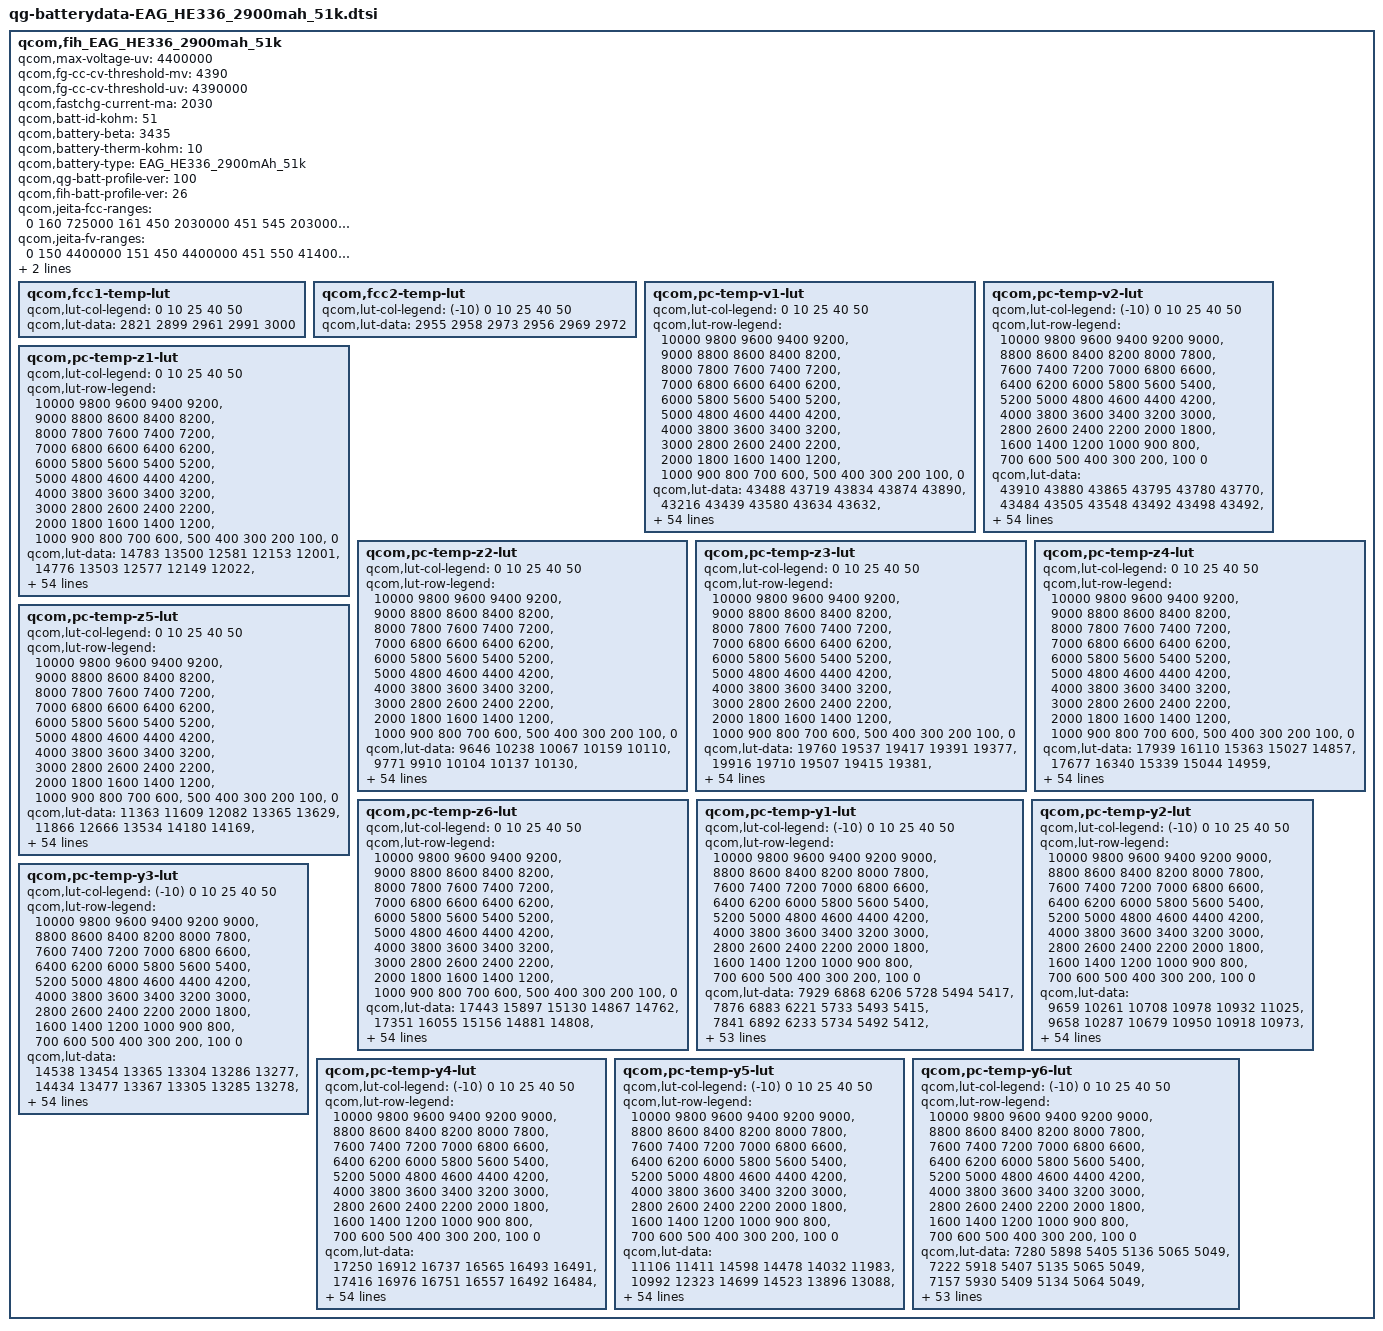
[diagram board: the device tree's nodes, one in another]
qcom,fih_EAG_HE336_2900mah_51k {
	/* 3486571_FIH_EaglesScud_2990mAh_averaged_MasterSlave_Jul3rd2018 */
	qcom,max-voltage-uv = <4400000>;
	qcom,fg-cc-cv-threshold-mv = <4390>;
	qcom,fg-cc-cv-threshold-uv = <4390000>;
	qcom,fastchg-current-ma = <2030>;
	qcom,batt-id-kohm = <51>;
	qcom,battery-beta = <3435>;
	qcom,battery-therm-kohm = <10>;
	qcom,battery-type =
		"EAG_HE336_2900mAh_51k";
	qcom,qg-batt-profile-ver = <100>;
	qcom,fih-batt-profile-ver = <26>; // RHD 51K use 25

	qcom,jeita-fcc-ranges = <0   160   725000
				 161 450  2030000
				 451 545  2030000
				 546 550  100000>;
	qcom,jeita-fv-ranges =  <0   150  4400000
				 151 450  4400000
				 451 550  4140000>;

	qcom,jeita-soft-thresholds = <0x257d 0xfb3>; 
	qcom,jeita-hard-thresholds = <0x3733 0xc19>;

	qcom,fcc1-temp-lut {
		qcom,lut-col-legend = <0 10 25 40 50>;
		qcom,lut-data = <2821 2899 2961 2991 3000>;
	};

	qcom,fcc2-temp-lut {
		qcom,lut-col-legend = <(-10) 0 10 25 40 50>;
		qcom,lut-data = <2955 2958 2973 2956 2969 2972>;
	};

	qcom,pc-temp-v1-lut {
		qcom,lut-col-legend = <0 10 25 40 50>;
		qcom,lut-row-legend = <10000 9800 9600 9400 9200>,
			<9000 8800 8600 8400 8200>,
			<8000 7800 7600 7400 7200>,
			<7000 6800 6600 6400 6200>,
			<6000 5800 5600 5400 5200>,
			<5000 4800 4600 4400 4200>,
			<4000 3800 3600 3400 3200>,
			<3000 2800 2600 2400 2200>,
			<2000 1800 1600 1400 1200>,
			<1000 900 800 700 600>,
			<500 400 300 200 100>,
			<0>;
		qcom,lut-data = <43488 43719 43834 43874 43890>,
			<43216 43439 43580 43634 43632>,
			<42958 43182 43330 43388 43393>,
			<42716 42938 43086 43147 43155>,
			<42489 42699 42845 42909 42920>,
			<42268 42464 42606 42672 42686>,
			<42052 42235 42368 42437 42453>,
			<41843 42015 42134 42203 42222>,
			<41638 41802 41906 41972 41992>,
			<41437 41593 41683 41741 41761>,
			<41241 41386 41464 41515 41532>,
			<41055 41185 41249 41293 41311>,
			<40880 40998 41041 41076 41093>,
			<40679 40826 40851 40869 40883>,
			<40394 40629 40670 40669 40676>,
			<40090 40348 40470 40475 40477>,
			<39901 40059 40229 40281 40285>,
			<39786 39889 40005 40092 40101>,
			<39685 39788 39852 39920 39929>,
			<39572 39687 39730 39768 39774>,
			<39458 39555 39581 39603 39609>,
			<39340 39403 39383 39383 39402>,
			<39213 39225 39175 39144 39171>,
			<39085 38987 38978 38959 38981>,
			<38964 38769 38786 38810 38821>,
			<38847 38637 38649 38682 38683>,
			<38736 38538 38562 38569 38565>,
			<38629 38468 38490 38468 38461>,
			<38527 38419 38413 38376 38367>,
			<38448 38381 38337 38292 38279>,
			<38390 38340 38270 38218 38202>,
			<38343 38301 38211 38151 38133>,
			<38305 38264 38159 38092 38072>,
			<38275 38227 38114 38041 38015>,
			<38246 38192 38075 37998 37965>,
			<38215 38158 38037 37955 37914>,
			<38183 38128 38001 37908 37855>,
			<38143 38090 37962 37856 37790>,
			<38089 38027 37903 37789 37717>,
			<38020 37936 37816 37705 37634>,
			<37926 37834 37717 37607 37539>,
			<37792 37715 37604 37497 37429>,
			<37653 37579 37473 37370 37300>,
			<37506 37416 37312 37209 37138>,
			<37360 37269 37171 37069 37002>,
			<37252 37170 37074 36981 36921>,
			<37213 37145 37047 36959 36898>,
			<37182 37118 37032 36940 36879>,
			<37154 37093 37012 36922 36862>,
			<37103 37051 36970 36871 36804>,
			<36911 36842 36742 36610 36520>,
			<36479 36402 36310 36175 36083>,
			<35915 35835 35744 35605 35511>,
			<35159 35064 34975 34825 34732>,
			<33922 33850 33772 33618 33523>,
			<30000 30000 30000 30000 30000>;
	};

	qcom,pc-temp-v2-lut {
		qcom,lut-col-legend = <(-10) 0 10 25 40 50>;
		qcom,lut-row-legend = <10000 9800 9600 9400 9200 9000>,
			<8800 8600 8400 8200 8000 7800>,
			<7600 7400 7200 7000 6800 6600>,
			<6400 6200 6000 5800 5600 5400>,
			<5200 5000 4800 4600 4400 4200>,
			<4000 3800 3600 3400 3200 3000>,
			<2800 2600 2400 2200 2000 1800>,
			<1600 1400 1200 1000 900 800>,
			<700 600 500 400 300 200>,
			<100 0>;
		qcom,lut-data = <43910 43880 43865 43795 43780 43770>,
			<43484 43505 43548 43492 43498 43492>,
			<43098 43165 43252 43208 43230 43227>,
			<42755 42867 42978 42946 42976 42975>,
			<42445 42606 42727 42705 42736 42737>,
			<42172 42358 42485 42471 42501 42503>,
			<41937 42110 42246 42236 42266 42268>,
			<41726 41869 42012 42005 42034 42036>,
			<41515 41616 41785 41779 41805 41807>,
			<41281 41333 41561 41556 41579 41580>,
			<41092 41111 41347 41338 41356 41357>,
			<40996 41010 41151 41126 41139 41138>,
			<40917 40937 40964 40918 40925 40922>,
			<40737 40784 40757 40706 40718 40716>,
			<40169 40384 40527 40484 40514 40515>,
			<39621 39980 40289 40272 40317 40321>,
			<39409 39758 40046 40080 40131 40133>,
			<39270 39588 39801 39902 39952 39951>,
			<39119 39408 39589 39734 39780 39778>,
			<38945 39216 39407 39585 39619 39619>,
			<38777 39029 39232 39426 39448 39450>,
			<38621 38853 39049 39213 39226 39229>,
			<38474 38687 38870 38963 38980 38985>,
			<38358 38535 38712 38766 38788 38795>,
			<38266 38394 38573 38622 38643 38647>,
			<38190 38272 38448 38500 38518 38521>,
			<38131 38174 38339 38391 38406 38408>,
			<38083 38091 38240 38294 38307 38308>,
			<38036 38027 38148 38205 38217 38217>,
			<37990 37980 38059 38125 38134 38133>,
			<37945 37941 37982 38052 38060 38056>,
			<37899 37902 37914 37981 37993 37987>,
			<37854 37866 37856 37914 37932 37923>,
			<37806 37828 37810 37850 37868 37857>,
			<37754 37789 37778 37792 37801 37789>,
			<37699 37747 37746 37735 37730 37714>,
			<37639 37699 37706 37675 37643 37614>,
			<37573 37646 37661 37615 37543 37495>,
			<37502 37584 37606 37549 37454 37394>,
			<37426 37512 37539 37481 37383 37318>,
			<37346 37429 37460 37405 37310 37242>,
			<37267 37328 37367 37312 37214 37146>,
			<37189 37205 37254 37195 37097 37034>,
			<37113 37082 37104 37056 36956 36895>,
			<37036 36969 36962 36924 36847 36792>,
			<36945 36891 36884 36878 36811 36756>,
			<36887 36855 36858 36864 36801 36745>,
			<36823 36819 36832 36843 36783 36730>,
			<36735 36776 36794 36818 36751 36698>,
			<36595 36689 36709 36747 36651 36578>,
			<36346 36468 36464 36491 36343 36242>,
			<35944 36026 35990 36020 35843 35735>,
			<35359 35414 35348 35412 35193 35078>,
			<34502 34544 34469 34594 34312 34187>,
			<33035 33164 33243 33342 33005 32858>,
			<29054 29382 28326 28910 28501 28490>;
	};

	qcom,pc-temp-z1-lut {
		qcom,lut-col-legend = <0 10 25 40 50>;
		qcom,lut-row-legend = <10000 9800 9600 9400 9200>,
			<9000 8800 8600 8400 8200>,
			<8000 7800 7600 7400 7200>,
			<7000 6800 6600 6400 6200>,
			<6000 5800 5600 5400 5200>,
			<5000 4800 4600 4400 4200>,
			<4000 3800 3600 3400 3200>,
			<3000 2800 2600 2400 2200>,
			<2000 1800 1600 1400 1200>,
			<1000 900 800 700 600>,
			<500 400 300 200 100>,
			<0>;
		qcom,lut-data = <14783 13500 12581 12153 12001>,
			<14776 13503 12577 12149 12022>,
			<14773 13492 12571 12147 12019>,
			<14776 13477 12562 12142 12016>,
			<14780 13471 12549 12131 12011>,
			<14783 13469 12538 12120 12007>,
			<14785 13468 12527 12115 12005>,
			<14787 13461 12520 12111 12003>,
			<14789 13447 12516 12109 12002>,
			<14786 13441 12513 12107 12000>,
			<14774 13438 12512 12107 11998>,
			<14738 13434 12516 12108 11998>,
			<14669 13421 12519 12109 11998>,
			<14604 13391 12509 12108 11998>,
			<14547 13366 12487 12103 11997>,
			<14497 13349 12480 12099 11997>,
			<14469 13338 12479 12100 11998>,
			<14456 13340 12479 12102 12000>,
			<14460 13363 12485 12105 12002>,
			<14502 13386 12500 12108 12002>,
			<14581 13397 12511 12110 12003>,
			<14630 13406 12517 12110 12004>,
			<14637 13415 12522 12111 12005>,
			<14634 13427 12526 12112 12007>,
			<14633 13435 12530 12115 12010>,
			<14642 13437 12534 12120 12014>,
			<14650 13434 12541 12124 12017>,
			<14655 13435 12549 12129 12020>,
			<14665 13453 12554 12134 12024>,
			<14680 13472 12560 12139 12028>,
			<14703 13476 12565 12145 12032>,
			<14725 13473 12570 12149 12035>,
			<14734 13474 12576 12152 12037>,
			<14739 13489 12582 12156 12040>,
			<14741 13507 12589 12162 12044>,
			<14730 13517 12597 12168 12047>,
			<14706 13527 12609 12172 12051>,
			<14698 13537 12621 12177 12054>,
			<14724 13554 12625 12181 12058>,
			<14759 13581 12627 12186 12060>,
			<14782 13593 12630 12190 12063>,
			<14800 13594 12637 12194 12066>,
			<14799 13597 12644 12197 12070>,
			<14778 13613 12648 12202 12074>,
			<14797 13602 12659 12207 12077>,
			<14796 13591 12669 12208 12077>,
			<14767 13596 12654 12212 12080>,
			<14738 13600 12669 12214 12080>,
			<14731 13602 12675 12215 12084>,
			<14783 13629 12664 12223 12088>,
			<14846 13641 12682 12234 12095>,
			<14805 13649 12698 12245 12105>,
			<14816 13696 12735 12257 12117>,
			<14903 13740 12763 12281 12132>,
			<14903 13740 12763 12281 12132>,
			<14903 13740 12763 12281 12132>;
	};

	qcom,pc-temp-z2-lut {
		qcom,lut-col-legend = <0 10 25 40 50>;
		qcom,lut-row-legend = <10000 9800 9600 9400 9200>,
			<9000 8800 8600 8400 8200>,
			<8000 7800 7600 7400 7200>,
			<7000 6800 6600 6400 6200>,
			<6000 5800 5600 5400 5200>,
			<5000 4800 4600 4400 4200>,
			<4000 3800 3600 3400 3200>,
			<3000 2800 2600 2400 2200>,
			<2000 1800 1600 1400 1200>,
			<1000 900 800 700 600>,
			<500 400 300 200 100>,
			<0>;
		qcom,lut-data = <9646 10238 10067 10159 10110>,
			<9771 9910 10104 10137 10130>,
			<9857 9912 10118 10190 10136>,
			<9887 9910 10107 10196 10132>,
			<9905 9900 10082 10158 10121>,
			<9911 9878 10061 10130 10108>,
			<9902 9856 10040 10129 10085>,
			<9885 9844 10028 10129 10042>,
			<9875 9835 10037 10131 10023>,
			<9870 9830 10057 10135 10027>,
			<9865 9828 10068 10138 10036>,
			<9856 9827 10072 10133 10043>,
			<9841 9866 10077 10122 10051>,
			<9832 10004 10092 10116 10054>,
			<9828 10079 10115 10113 10053>,
			<9825 10007 10121 10111 10053>,
			<9828 9906 10107 10106 10056>,
			<9855 9893 10094 10103 10061>,
			<9883 9928 10104 10106 10069>,
			<9882 9963 10137 10128 10086>,
			<9862 9982 10170 10162 10113>,
			<9847 9996 10208 10232 10171>,
			<9828 10003 10234 10318 10247>,
			<9808 10007 10212 10322 10265>,
			<9805 10010 10150 10239 10252>,
			<9807 10015 10125 10181 10235>,
			<9810 10023 10147 10212 10208>,
			<9816 10027 10171 10264 10163>,
			<9823 10025 10175 10264 10127>,
			<9827 10022 10176 10200 10096>,
			<9827 10021 10175 10156 10071>,
			<9827 10021 10172 10164 10053>,
			<9829 10022 10168 10181 10039>,
			<9831 10030 10173 10198 10041>,
			<9835 10042 10191 10217 10079>,
			<9840 10045 10205 10240 10129>,
			<9848 10045 10211 10275 10188>,
			<9858 10046 10217 10317 10250>,
			<9871 10055 10232 10350 10266>,
			<9885 10072 10265 10379 10266>,
			<9897 10083 10284 10393 10266>,
			<9909 10087 10283 10378 10268>,
			<9883 10093 10280 10362 10269>,
			<9762 10105 10288 10365 10273>,
			<9869 10229 10328 10359 10261>,
			<10119 10275 10339 10297 10227>,
			<10445 10368 10344 10317 10241>,
			<10348 10387 10374 10312 10242>,
			<10202 10411 10407 10339 10305>,
			<10227 10492 10407 10391 10443>,
			<10038 10481 10501 10351 10172>,
			<9724 10337 10492 10237 10102>,
			<9585 10203 10543 10203 10027>,
			<9413 10113 10391 10131 9988>,
			<9413 10113 10391 10131 9988>,
			<9413 10113 10391 10131 9988>;
	};

	qcom,pc-temp-z3-lut {
		qcom,lut-col-legend = <0 10 25 40 50>;
		qcom,lut-row-legend = <10000 9800 9600 9400 9200>,
			<9000 8800 8600 8400 8200>,
			<8000 7800 7600 7400 7200>,
			<7000 6800 6600 6400 6200>,
			<6000 5800 5600 5400 5200>,
			<5000 4800 4600 4400 4200>,
			<4000 3800 3600 3400 3200>,
			<3000 2800 2600 2400 2200>,
			<2000 1800 1600 1400 1200>,
			<1000 900 800 700 600>,
			<500 400 300 200 100>,
			<0>;
		qcom,lut-data = <19760 19537 19417 19391 19377>,
			<19916 19710 19507 19415 19381>,
			<19998 19777 19556 19446 19407>,
			<19980 19819 19564 19458 19423>,
			<19890 19827 19568 19464 19434>,
			<19828 19826 19568 19467 19440>,
			<19819 19823 19567 19463 19435>,
			<19813 19815 19565 19452 19420>,
			<19812 19801 19554 19444 19413>,
			<19816 19790 19534 19438 19410>,
			<19819 19784 19524 19431 19407>,
			<19813 19778 19521 19423 19402>,
			<19792 19769 19518 19414 19395>,
			<19777 19757 19503 19408 19390>,
			<19785 19744 19478 19402 19386>,
			<19799 19730 19471 19398 19383>,
			<19790 19713 19480 19397 19381>,
			<19730 19688 19489 19395 19378>,
			<19679 19645 19484 19393 19375>,
			<19696 19619 19470 19387 19365>,
			<19756 19625 19467 19383 19357>,
			<19798 19642 19488 19395 19364>,
			<19865 19658 19510 19414 19378>,
			<19945 19676 19505 19413 19381>,
			<19964 19688 19489 19387 19378>,
			<19967 19688 19478 19369 19375>,
			<19968 19685 19474 19392 19390>,
			<19969 19682 19471 19431 19418>,
			<19971 19677 19478 19439 19425>,
			<19970 19671 19501 19439 19419>,
			<19962 19668 19511 19438 19411>,
			<19948 19666 19510 19434 19403>,
			<19934 19664 19510 19427 19393>,
			<19917 19662 19507 19420 19385>,
			<19899 19659 19500 19413 19379>,
			<19882 19654 19494 19406 19375>,
			<19865 19645 19489 19402 19375>,
			<19846 19637 19484 19399 19374>,
			<19819 19631 19479 19397 19374>,
			<19793 19626 19474 19397 19371>,
			<19779 19620 19470 19396 19369>,
			<19772 19613 19467 19392 19369>,
			<19707 19602 19463 19389 19369>,
			<19500 19585 19458 19388 19376>,
			<19283 19530 19437 19382 19373>,
			<19262 19484 19427 19371 19358>,
			<19260 19392 19424 19358 19346>,
			<19261 19369 19400 19359 19348>,
			<19261 19348 19384 19358 19338>,
			<19261 19334 19383 19348 19326>,
			<19262 19348 19373 19364 19366>,
			<19265 19356 19361 19372 19372>,
			<19268 19337 19352 19371 19373>,
			<19274 19346 19363 19382 19368>,
			<19274 19346 19363 19382 19368>,
			<19274 19346 19363 19382 19368>;
	};

	qcom,pc-temp-z4-lut {
		qcom,lut-col-legend = <0 10 25 40 50>;
		qcom,lut-row-legend = <10000 9800 9600 9400 9200>,
			<9000 8800 8600 8400 8200>,
			<8000 7800 7600 7400 7200>,
			<7000 6800 6600 6400 6200>,
			<6000 5800 5600 5400 5200>,
			<5000 4800 4600 4400 4200>,
			<4000 3800 3600 3400 3200>,
			<3000 2800 2600 2400 2200>,
			<2000 1800 1600 1400 1200>,
			<1000 900 800 700 600>,
			<500 400 300 200 100>,
			<0>;
		qcom,lut-data = <17939 16110 15363 15027 14857>,
			<17677 16340 15339 15044 14959>,
			<17408 16147 15296 15008 14934>,
			<17126 15760 15207 14968 14905>,
			<16828 15509 15078 14916 14866>,
			<16564 15351 14989 14869 14829>,
			<16341 15230 14926 14834 14807>,
			<16145 15136 14881 14806 14790>,
			<15991 15062 14851 14789 14776>,
			<15870 15004 14829 14777 14766>,
			<15765 14962 14817 14769 14757>,
			<15655 14923 14811 14764 14749>,
			<15546 14867 14805 14759 14742>,
			<15481 14797 14795 14754 14734>,
			<15456 14765 14781 14743 14726>,
			<15435 14805 14773 14732 14718>,
			<15411 14862 14766 14723 14710>,
			<15376 14868 14759 14715 14702>,
			<15332 14841 14749 14710 14698>,
			<15264 14814 14738 14705 14695>,
			<15161 14798 14735 14703 14694>,
			<15081 14786 14758 14739 14725>,
			<14988 14793 14795 14810 14793>,
			<14898 14894 14852 14858 14828>,
			<14882 14990 14932 14895 14846>,
			<14885 14999 14960 14913 14855>,
			<14891 15002 14939 14876 14827>,
			<14903 15002 14904 14808 14771>,
			<14920 14977 14869 14774 14744>,
			<14927 14939 14829 14755 14734>,
			<14924 14910 14805 14744 14727>,
			<14919 14885 14792 14738 14721>,
			<14912 14863 14784 14734 14717>,
			<14899 14844 14781 14733 14715>,
			<14885 14827 14779 14732 14713>,
			<14873 14812 14777 14732 14713>,
			<14861 14797 14775 14735 14719>,
			<14854 14788 14772 14743 14731>,
			<14849 14787 14773 14748 14738>,
			<14845 14786 14776 14752 14742>,
			<14839 14784 14778 14754 14744>,
			<14831 14772 14764 14744 14735>,
			<14875 14762 14747 14733 14723>,
			<15053 14758 14741 14733 14723>,
			<15144 14739 14723 14720 14713>,
			<15144 14754 14699 14705 14699>,
			<15138 14841 14691 14700 14695>,
			<15124 14858 14695 14676 14670>,
			<15112 14873 14700 14655 14655>,
			<15104 14881 14694 14663 14662>,
			<15102 14873 14729 14683 14665>,
			<15128 14886 14753 14681 14664>,
			<15151 14920 14766 14684 14666>,
			<15176 14924 14763 14675 14671>,
			<15176 14924 14763 14675 14671>,
			<15176 14924 14763 14675 14671>;
	};

	qcom,pc-temp-z5-lut {
		qcom,lut-col-legend = <0 10 25 40 50>;
		qcom,lut-row-legend = <10000 9800 9600 9400 9200>,
			<9000 8800 8600 8400 8200>,
			<8000 7800 7600 7400 7200>,
			<7000 6800 6600 6400 6200>,
			<6000 5800 5600 5400 5200>,
			<5000 4800 4600 4400 4200>,
			<4000 3800 3600 3400 3200>,
			<3000 2800 2600 2400 2200>,
			<2000 1800 1600 1400 1200>,
			<1000 900 800 700 600>,
			<500 400 300 200 100>,
			<0>;
		qcom,lut-data = <11363 11609 12082 13365 13629>,
			<11866 12666 13534 14180 14169>,
			<12206 13333 14537 15332 15408>,
			<12307 13858 15020 15978 16374>,
			<12332 14334 15358 16381 17276>,
			<12375 14760 15830 16701 17812>,
			<12505 15179 16538 17066 17693>,
			<12689 15617 17080 17407 17378>,
			<12854 16069 17258 17501 17309>,
			<13027 16612 17368 17581 17697>,
			<13141 17353 17542 17648 18053>,
			<13117 18233 17871 17531 17961>,
			<13010 19318 18115 17244 17739>,
			<12943 20682 17800 17101 17700>,
			<13018 21293 17005 17003 17985>,
			<13129 20577 16811 17143 18422>,
			<13061 19386 17641 17662 19063>,
			<12640 18607 18772 18333 19847>,
			<12284 17914 19578 18783 19993>,
			<12548 17546 20409 19051 19285>,
			<13560 19649 22135 19476 18669>,
			<14781 24651 28944 22342 19597>,
			<17648 29386 35107 26472 21437>,
			<21566 34789 32936 26152 21439>,
			<24454 38418 25532 19259 17640>,
			<26718 37247 20864 14513 14649>,
			<28769 33267 18736 15357 15602>,
			<31080 30074 17541 17168 17810>,
			<33398 27792 18138 18809 19308>,
			<34213 26221 20566 20484 20365>,
			<33206 26003 23027 22109 21089>,
			<31572 26188 25434 23783 21459>,
			<30151 26512 27587 25354 21741>,
			<28134 27655 28936 26195 22145>,
			<26161 29159 30023 26767 23382>,
			<24686 29533 30419 27018 24265>,
			<23402 29375 30144 26651 24219>,
			<22311 29271 29634 25816 24054>,
			<20898 29584 28809 24868 23576>,
			<19771 30103 27034 23559 21718>,
			<19856 30132 25907 22416 20219>,
			<20599 28344 25687 21692 20054>,
			<19501 26275 25437 21131 20144>,
			<14711 24460 24355 20544 20901>,
			<11316 22288 22952 20425 20897>,
			<10936 18649 22977 19479 18683>,
			<10918 13107 22860 17751 17060>,
			<10912 12433 18156 19252 19377>,
			<10917 12048 16646 21320 20060>,
			<10929 11871 16583 18924 16884>,
			<10983 12184 14930 17286 20306>,
			<10967 12168 13682 17260 19837>,
			<10889 11726 13054 16510 18950>,
			<10837 11686 13205 17338 16772>,
			<10837 11686 13205 17338 16772>,
			<10837 11686 13205 17338 16772>;
	};

	qcom,pc-temp-z6-lut {
		qcom,lut-col-legend = <0 10 25 40 50>;
		qcom,lut-row-legend = <10000 9800 9600 9400 9200>,
			<9000 8800 8600 8400 8200>,
			<8000 7800 7600 7400 7200>,
			<7000 6800 6600 6400 6200>,
			<6000 5800 5600 5400 5200>,
			<5000 4800 4600 4400 4200>,
			<4000 3800 3600 3400 3200>,
			<3000 2800 2600 2400 2200>,
			<2000 1800 1600 1400 1200>,
			<1000 900 800 700 600>,
			<500 400 300 200 100>,
			<0>;
		qcom,lut-data = <17443 15897 15130 14867 14762>,
			<17351 16055 15156 14881 14808>,
			<17230 15976 15162 14881 14810>,
			<17071 15813 15130 14877 14809>,
			<16860 15696 15066 14857 14799>,
			<16677 15612 15023 14834 14784>,
			<16546 15543 14994 14815 14770>,
			<16438 15485 14969 14797 14755>,
			<16352 15437 14946 14785 14745>,
			<16287 15398 14926 14776 14739>,
			<16227 15371 14917 14768 14733>,
			<16151 15346 14913 14762 14727>,
			<16066 15310 14909 14755 14720>,
			<16003 15263 14894 14748 14713>,
			<15967 15242 14870 14739 14707>,
			<15939 15245 14862 14732 14701>,
			<15905 15250 14863 14727 14697>,
			<15859 15246 14864 14724 14693>,
			<15826 15215 14859 14720 14688>,
			<15818 15193 14850 14715 14682>,
			<15814 15195 14848 14712 14678>,
			<15812 15201 14868 14736 14695>,
			<15818 15215 14897 14778 14731>,
			<15827 15270 14923 14792 14748>,
			<15836 15319 14949 14797 14756>,
			<15843 15325 14957 14799 14760>,
			<15852 15328 14946 14795 14756>,
			<15862 15328 14932 14787 14748>,
			<15874 15317 14925 14780 14741>,
			<15879 15300 14920 14774 14734>,
			<15875 15288 14915 14767 14728>,
			<15869 15279 14912 14762 14721>,
			<15861 15271 14909 14757 14714>,
			<15850 15266 14906 14753 14709>,
			<15839 15261 14903 14748 14704>,
			<15833 15256 14901 14746 14702>,
			<15829 15249 14899 14747 14704>,
			<15824 15245 14897 14748 14709>,
			<15818 15246 14897 14750 14711>,
			<15813 15251 14899 14752 14712>,
			<15812 15252 14899 14753 14713>,
			<15812 15250 14894 14747 14709>,
			<15809 15247 14888 14741 14705>,
			<15790 15245 14885 14742 14708>,
			<15733 15219 14870 14734 14704>,
			<15727 15210 14857 14722 14689>,
			<15725 15198 14852 14713 14682>,
			<15719 15197 14844 14704 14672>,
			<15717 15196 14839 14695 14660>,
			<15722 15198 14839 14694 14658>,
			<15737 15211 14853 14713 14682>,
			<15763 15233 14862 14719 14687>,
			<15791 15252 14870 14723 14691>,
			<15839 15276 14884 14730 14695>,
			<15839 15276 14884 14730 14695>,
			<15839 15276 14884 14730 14695>;
	};

	qcom,pc-temp-y1-lut {
		qcom,lut-col-legend = <(-10) 0 10 25 40 50>;
		qcom,lut-row-legend = <10000 9800 9600 9400 9200 9000>,
			<8800 8600 8400 8200 8000 7800>,
			<7600 7400 7200 7000 6800 6600>,
			<6400 6200 6000 5800 5600 5400>,
			<5200 5000 4800 4600 4400 4200>,
			<4000 3800 3600 3400 3200 3000>,
			<2800 2600 2400 2200 2000 1800>,
			<1600 1400 1200 1000 900 800>,
			<700 600 500 400 300 200>,
			<100 0>;
		qcom,lut-data = <7929 6868 6206 5728 5494 5417>,
			<7876 6883 6221 5733 5493 5415>,
			<7841 6892 6233 5734 5492 5412>,
			<7820 6896 6241 5735 5490 5409>,
			<7810 6898 6247 5734 5488 5407>,
			<7807 6898 6249 5732 5486 5406>,
			<7820 6898 6245 5729 5484 5406>,
			<7842 6897 6240 5725 5480 5406>,
			<7843 6898 6240 5723 5478 5406>,
			<7817 6906 6247 5721 5475 5406>,
			<7797 6911 6252 5719 5473 5405>,
			<7809 6904 6245 5717 5471 5403>,
			<7837 6894 6234 5715 5469 5401>,
			<7850 6893 6232 5713 5468 5400>,
			<7851 6909 6239 5713 5468 5401>,
			<7851 6925 6246 5713 5468 5402>,
			<7852 6932 6252 5716 5469 5402>,
			<7856 6938 6259 5724 5469 5402>,
			<7862 6941 6260 5728 5470 5402>,
			<7875 6941 6257 5726 5470 5403>,
			<7887 6941 6254 5725 5470 5403>,
			<7873 6938 6255 5727 5471 5404>,
			<7838 6933 6256 5731 5473 5405>,
			<7820 6927 6257 5734 5474 5407>,
			<7817 6923 6260 5735 5476 5409>,
			<7817 6921 6263 5736 5478 5410>,
			<7814 6923 6262 5738 5480 5411>,
			<7810 6929 6260 5741 5482 5411>,
			<7810 6932 6260 5744 5484 5412>,
			<7838 6937 6270 5751 5487 5413>,
			<7868 6942 6279 5757 5490 5415>,
			<7862 6939 6281 5758 5493 5419>,
			<7845 6926 6282 5759 5498 5424>,
			<7833 6921 6283 5760 5501 5426>,
			<7817 6929 6284 5765 5503 5427>,
			<7803 6940 6285 5771 5505 5428>,
			<7808 6944 6287 5774 5508 5430>,
			<7828 6945 6288 5775 5512 5434>,
			<7839 6945 6289 5776 5515 5436>,
			<7855 6939 6290 5780 5517 5437>,
			<7878 6932 6290 5786 5519 5438>,
			<7883 6935 6297 5790 5521 5441>,
			<7875 6950 6307 5795 5524 5444>,
			<7858 6946 6298 5798 5529 5446>,
			<7826 6929 6291 5804 5536 5448>,
			<7859 6966 6302 5813 5540 5452>,
			<7912 6998 6315 5809 5543 5452>,
			<7829 6972 6317 5821 5542 5452>,
			<7896 6999 6309 5827 5542 5452>,
			<7907 6936 6313 5827 5542 5452>,
			<7908 6981 6327 5824 5546 5455>,
			<7877 7007 6333 5833 5553 5462>,
			<7961 7034 6341 5852 5563 5470>,
			<7987 7058 6368 5868 5579 5481>,
			<7987 7058 6368 5868 5579 5481>,
			<7987 7058 6368 5868 5579 5481>;
	};

	qcom,pc-temp-y2-lut {
		qcom,lut-col-legend = <(-10) 0 10 25 40 50>;
		qcom,lut-row-legend = <10000 9800 9600 9400 9200 9000>,
			<8800 8600 8400 8200 8000 7800>,
			<7600 7400 7200 7000 6800 6600>,
			<6400 6200 6000 5800 5600 5400>,
			<5200 5000 4800 4600 4400 4200>,
			<4000 3800 3600 3400 3200 3000>,
			<2800 2600 2400 2200 2000 1800>,
			<1600 1400 1200 1000 900 800>,
			<700 600 500 400 300 200>,
			<100 0>;
		qcom,lut-data = <9659 10261 10708 10978 10932 11025>,
			<9658 10287 10679 10950 10918 10973>,
			<9657 10306 10651 10910 10893 10911>,
			<9658 10319 10623 10868 10863 10848>,
			<9660 10327 10599 10830 10833 10794>,
			<9663 10329 10578 10804 10811 10760>,
			<9717 10324 10559 10789 10792 10742>,
			<9808 10315 10542 10775 10772 10728>,
			<9818 10312 10534 10760 10759 10720>,
			<9732 10309 10530 10728 10747 10713>,
			<9666 10312 10525 10702 10740 10707>,
			<9666 10361 10510 10689 10741 10705>,
			<9668 10442 10490 10672 10743 10705>,
			<9668 10472 10502 10669 10743 10703>,
			<9664 10460 10611 10678 10733 10684>,
			<9661 10452 10692 10692 10726 10670>,
			<9661 10480 10689 10723 10738 10674>,
			<9661 10525 10680 10777 10769 10686>,
			<9661 10548 10680 10829 10812 10711>,
			<9660 10555 10693 10886 10896 10795>,
			<9660 10562 10705 10924 10955 10860>,
			<9659 10573 10711 10919 10951 10858>,
			<9659 10588 10715 10903 10939 10846>,
			<9659 10598 10722 10898 10930 10849>,
			<9659 10607 10741 10919 10925 10883>,
			<9658 10612 10760 10944 10926 10925>,
			<9657 10439 10774 10954 10948 10957>,
			<9657 9965 10791 10961 10988 10986>,
			<9656 9754 10800 10964 11009 11001>,
			<9656 9738 10810 10964 11026 11015>,
			<9655 9728 10818 10965 11042 11026>,
			<9655 9713 10810 10970 11060 11031>,
			<9655 9695 10790 10983 11088 11040>,
			<9654 9683 10782 10988 11095 11044>,
			<9654 9677 10776 10981 11062 11043>,
			<9653 9672 10767 10969 11029 11042>,
			<9653 9667 10754 10955 11022 11028>,
			<9653 9663 10727 10937 11019 10992>,
			<9653 9660 10696 10927 11012 10979>,
			<9653 9658 10657 10922 10987 10979>,
			<9653 9656 10609 10915 10965 10978>,
			<9653 9654 10555 10894 10986 10960>,
			<9652 9653 10485 10846 11034 10926>,
			<9652 9653 10259 10827 11021 10916>,
			<9652 9652 9977 10810 10980 10903>,
			<9652 9652 9772 10739 10900 10855>,
			<9652 9652 9750 10732 10874 10799>,
			<9652 9652 9710 10715 10854 10770>,
			<9652 9651 9683 10732 10864 10765>,
			<9652 9651 9671 10708 10845 10736>,
			<9652 9651 9667 10670 10806 10716>,
			<9652 9651 9663 10603 10753 10644>,
			<9651 9651 9658 10564 10674 10591>,
			<9651 9651 9655 10513 10610 10500>,
			<9651 9651 9655 10513 10610 10500>,
			<9651 9651 9655 10513 10610 10500>;
	};

	qcom,pc-temp-y3-lut {
		qcom,lut-col-legend = <(-10) 0 10 25 40 50>;
		qcom,lut-row-legend = <10000 9800 9600 9400 9200 9000>,
			<8800 8600 8400 8200 8000 7800>,
			<7600 7400 7200 7000 6800 6600>,
			<6400 6200 6000 5800 5600 5400>,
			<5200 5000 4800 4600 4400 4200>,
			<4000 3800 3600 3400 3200 3000>,
			<2800 2600 2400 2200 2000 1800>,
			<1600 1400 1200 1000 900 800>,
			<700 600 500 400 300 200>,
			<100 0>;
		qcom,lut-data = <14538 13454 13365 13304 13286 13277>,
			<14434 13477 13367 13305 13285 13278>,
			<14322 13496 13370 13306 13285 13280>,
			<14216 13511 13374 13307 13284 13281>,
			<14125 13521 13378 13308 13285 13283>,
			<14061 13526 13382 13309 13285 13284>,
			<14028 13523 13386 13309 13286 13284>,
			<14003 13516 13391 13309 13288 13284>,
			<13944 13516 13394 13309 13288 13284>,
			<13785 13522 13397 13312 13287 13285>,
			<13673 13524 13399 13315 13287 13285>,
			<13690 13497 13405 13316 13290 13285>,
			<13726 13452 13410 13317 13294 13286>,
			<13731 13442 13410 13319 13296 13286>,
			<13670 13455 13403 13324 13296 13290>,
			<13615 13466 13394 13327 13297 13293>,
			<13607 13463 13389 13327 13298 13292>,
			<13604 13453 13383 13326 13300 13291>,
			<13600 13444 13376 13326 13301 13291>,
			<13596 13435 13369 13327 13304 13296>,
			<13593 13425 13362 13328 13306 13300>,
			<13588 13416 13357 13324 13302 13297>,
			<13584 13407 13353 13313 13293 13289>,
			<13584 13400 13349 13307 13288 13284>,
			<13595 13394 13344 13304 13286 13281>,
			<13614 13387 13342 13302 13284 13279>,
			<13640 13358 13341 13302 13283 13279>,
			<13679 13300 13340 13302 13282 13279>,
			<13719 13278 13340 13303 13282 13280>,
			<13756 13281 13338 13304 13283 13280>,
			<13796 13288 13335 13306 13285 13280>,
			<13850 13299 13329 13306 13286 13280>,
			<13921 13321 13320 13304 13287 13280>,
			<13999 13345 13318 13303 13287 13280>,
			<14087 13370 13327 13303 13287 13281>,
			<14183 13400 13338 13303 13287 13283>,
			<14280 13442 13341 13302 13286 13282>,
			<14381 13499 13344 13301 13283 13279>,
			<14483 13570 13346 13300 13282 13278>,
			<14588 13658 13349 13300 13284 13280>,
			<14694 13768 13353 13301 13287 13281>,
			<14795 13902 13358 13301 13286 13281>,
			<14893 14076 13365 13302 13283 13281>,
			<15001 14266 13372 13304 13282 13281>,
			<15116 14474 13379 13308 13281 13280>,
			<15214 14661 13387 13314 13288 13283>,
			<15105 14612 13393 13314 13292 13287>,
			<15214 14739 13420 13314 13295 13292>,
			<15325 14874 13448 13324 13299 13296>,
			<15447 14986 13481 13331 13299 13294>,
			<15577 15110 13514 13329 13296 13289>,
			<15719 15219 13566 13329 13299 13290>,
			<15898 15374 13688 13342 13301 13296>,
			<16484 15530 13889 13357 13308 13299>,
			<16484 15530 13889 13357 13308 13299>,
			<16484 15530 13889 13357 13308 13299>;
	};

	qcom,pc-temp-y4-lut {
		qcom,lut-col-legend = <(-10) 0 10 25 40 50>;
		qcom,lut-row-legend = <10000 9800 9600 9400 9200 9000>,
			<8800 8600 8400 8200 8000 7800>,
			<7600 7400 7200 7000 6800 6600>,
			<6400 6200 6000 5800 5600 5400>,
			<5200 5000 4800 4600 4400 4200>,
			<4000 3800 3600 3400 3200 3000>,
			<2800 2600 2400 2200 2000 1800>,
			<1600 1400 1200 1000 900 800>,
			<700 600 500 400 300 200>,
			<100 0>;
		qcom,lut-data = <17250 16912 16737 16565 16493 16491>,
			<17416 16976 16751 16557 16492 16484>,
			<17570 17045 16770 16552 16492 16479>,
			<17698 17111 16788 16550 16491 16475>,
			<17787 17167 16803 16550 16491 16473>,
			<17823 17206 16810 16550 16492 16472>,
			<17790 17231 16810 16553 16492 16473>,
			<17731 17249 16807 16558 16493 16475>,
			<17766 17249 16810 16562 16496 16478>,
			<18135 17225 16823 16567 16503 16481>,
			<18479 17207 16841 16573 16509 16484>,
			<18603 17484 16859 16580 16511 16489>,
			<18700 18018 16882 16589 16513 16495>,
			<18643 18114 16927 16601 16516 16500>,
			<17914 17629 17039 16616 16527 16503>,
			<17285 17190 17114 16637 16541 16508>,
			<17271 17124 17058 16669 16555 16518>,
			<17285 17092 16943 16715 16572 16533>,
			<17285 17063 16879 16754 16597 16554>,
			<17214 17013 16850 16794 16644 16588>,
			<17125 16954 16820 16818 16677 16611>,
			<17066 16895 16764 16763 16637 16584>,
			<17016 16832 16696 16619 16550 16526>,
			<16996 16776 16656 16548 16509 16498>,
			<16992 16715 16634 16530 16494 16486>,
			<16988 16674 16619 16521 16487 16480>,
			<16981 16704 16611 16521 16488 16481>,
			<16973 16794 16606 16523 16492 16483>,
			<16970 16837 16599 16526 16497 16486>,
			<16979 16844 16588 16532 16504 16493>,
			<16992 16847 16579 16541 16513 16503>,
			<17000 16847 16581 16548 16528 16516>,
			<17007 16842 16590 16555 16546 16531>,
			<17013 16841 16594 16557 16552 16539>,
			<17019 16855 16591 16552 16552 16543>,
			<17024 16874 16590 16543 16551 16546>,
			<17025 16889 16599 16534 16535 16530>,
			<17026 16901 16617 16522 16497 16492>,
			<17027 16914 16637 16516 16482 16479>,
			<17034 16935 16661 16518 16485 16482>,
			<17046 16953 16685 16521 16489 16484>,
			<17065 16946 16709 16527 16492 16485>,
			<17098 16914 16729 16538 16494 16485>,
			<17142 16893 16740 16540 16487 16474>,
			<17200 16883 16756 16539 16481 16465>,
			<17253 16899 16779 16563 16493 16481>,
			<17168 16907 16788 16566 16502 16497>,
			<17201 16949 16830 16592 16526 16528>,
			<17241 17023 16893 16626 16565 16569>,
			<17242 17084 16969 16669 16571 16554>,
			<17229 17090 16966 16637 16514 16493>,
			<17200 17040 16945 16629 16505 16489>,
			<17199 17016 16969 16672 16528 16504>,
			<17398 17043 17028 16764 16607 16582>,
			<17398 17043 17028 16764 16607 16582>,
			<17398 17043 17028 16764 16607 16582>;
	};

	qcom,pc-temp-y5-lut {
		qcom,lut-col-legend = <(-10) 0 10 25 40 50>;
		qcom,lut-row-legend = <10000 9800 9600 9400 9200 9000>,
			<8800 8600 8400 8200 8000 7800>,
			<7600 7400 7200 7000 6800 6600>,
			<6400 6200 6000 5800 5600 5400>,
			<5200 5000 4800 4600 4400 4200>,
			<4000 3800 3600 3400 3200 3000>,
			<2800 2600 2400 2200 2000 1800>,
			<1600 1400 1200 1000 900 800>,
			<700 600 500 400 300 200>,
			<100 0>;
		qcom,lut-data = <11106 11411 14598 14478 14032 11983>,
			<10992 12323 14699 14523 13896 13088>,
			<10958 13097 14792 14491 13720 13929>,
			<10994 13697 14870 14407 13541 14517>,
			<11088 14089 14928 14295 13401 14865>,
			<11231 14237 14961 14179 13339 14983>,
			<12035 14122 14995 13941 13359 14786>,
			<13271 13829 15021 13584 13389 14387>,
			<13366 13375 14938 13373 13307 14091>,
			<11923 12362 14577 13345 12897 13864>,
			<10802 11670 14121 13297 12605 13639>,
			<12234 11861 13532 13075 12915 13334>,
			<15101 12424 12926 12820 13476 13038>,
			<15680 13315 12846 12748 13553 13040>,
			<13285 15511 13246 12766 13093 13499>,
			<11210 17147 13810 12785 12730 13849>,
			<11297 16881 14643 12781 12741 13505>,
			<11658 16214 15640 12791 12809 12849>,
			<11814 16017 16045 12972 12924 12723>,
			<11851 16215 16188 14401 13264 13167>,
			<11868 16422 16302 15846 13749 13793>,
			<11708 16429 16455 16231 14529 14614>,
			<11262 16335 16595 16469 15484 15536>,
			<10964 16292 16584 16515 15711 15702>,
			<10794 16164 16214 16154 15351 15115>,
			<10693 15840 15908 15765 14893 14583>,
			<10748 14499 16044 15742 14473 14464>,
			<10922 11792 16351 15840 14028 14363>,
			<10996 10697 16448 15993 13938 14333>,
			<10954 10661 16331 16636 14324 14327>,
			<10904 10645 16041 17309 14814 14313>,
			<10920 10696 15165 17346 15105 14234>,
			<11001 10874 13814 17216 15349 14087>,
			<11086 11019 13514 17161 15735 14139>,
			<11166 11119 14897 17329 16608 15327>,
			<11239 11224 16176 17481 17298 16423>,
			<11292 11364 16158 17275 16946 16257>,
			<11346 11561 15924 16698 15932 15743>,
			<11361 11667 15664 16193 15455 15567>,
			<11292 11691 15276 15815 16117 15637>,
			<11186 11702 14938 15412 16773 15703>,
			<11105 11740 14830 14936 15915 15474>,
			<11036 11854 14780 14406 14334 15024>,
			<11063 11759 14015 14425 14243 15604>,
			<11235 11531 12858 14768 14245 15935>,
			<11406 11582 11843 14611 14544 14240>,
			<11433 11417 11714 14737 15173 14413>,
			<11646 11482 11694 13745 14620 14796>,
			<11861 11619 11656 14175 14588 14628>,
			<12251 11923 11755 14215 14346 14487>,
			<12200 12126 11836 14727 15441 15006>,
			<11804 11633 11728 14570 16977 15732>,
			<11521 11630 11753 15150 16801 17070>,
			<11062 11517 12376 15901 17464 17545>,
			<11062 11517 12376 15901 17464 17545>,
			<11062 11517 12376 15901 17464 17545>;
	};

	qcom,pc-temp-y6-lut {
		qcom,lut-col-legend = <(-10) 0 10 25 40 50>;
		qcom,lut-row-legend = <10000 9800 9600 9400 9200 9000>,
			<8800 8600 8400 8200 8000 7800>,
			<7600 7400 7200 7000 6800 6600>,
			<6400 6200 6000 5800 5600 5400>,
			<5200 5000 4800 4600 4400 4200>,
			<4000 3800 3600 3400 3200 3000>,
			<2800 2600 2400 2200 2000 1800>,
			<1600 1400 1200 1000 900 800>,
			<700 600 500 400 300 200>,
			<100 0>;
		qcom,lut-data = <7280 5898 5405 5136 5065 5049>,
			<7222 5918 5407 5135 5065 5049>,
			<7157 5930 5409 5134 5064 5049>,
			<7093 5936 5409 5134 5064 5049>,
			<7036 5938 5409 5134 5064 5049>,
			<6996 5939 5409 5134 5064 5049>,
			<6969 5933 5408 5134 5065 5050>,
			<6947 5922 5405 5135 5066 5051>,
			<6930 5910 5405 5136 5067 5052>,
			<6891 5892 5407 5138 5068 5053>,
			<6864 5880 5409 5142 5070 5054>,
			<6895 5937 5413 5144 5073 5056>,
			<6957 6046 5420 5148 5075 5058>,
			<6951 6063 5431 5152 5079 5060>,
			<6720 5943 5453 5158 5082 5063>,
			<6520 5832 5468 5167 5086 5066>,
			<6511 5812 5451 5177 5091 5069>,
			<6512 5801 5414 5190 5097 5073>,
			<6509 5789 5391 5201 5106 5079>,
			<6491 5770 5378 5212 5120 5092>,
			<6473 5749 5364 5219 5130 5101>,
			<6465 5729 5344 5200 5116 5091>,
			<6460 5708 5322 5152 5085 5068>,
			<6459 5694 5309 5128 5069 5056>,
			<6472 5681 5302 5121 5063 5050>,
			<6495 5673 5298 5118 5060 5048>,
			<6518 5675 5298 5118 5060 5048>,
			<6546 5682 5298 5119 5061 5049>,
			<6578 5692 5298 5121 5062 5050>,
			<6614 5711 5298 5125 5065 5052>,
			<6655 5737 5298 5130 5070 5056>,
			<6704 5765 5298 5132 5075 5059>,
			<6764 5800 5299 5135 5081 5063>,
			<6828 5841 5302 5135 5083 5066>,
			<6897 5892 5312 5134 5083 5069>,
			<6970 5953 5327 5133 5083 5070>,
			<7044 6021 5341 5131 5078 5065>,
			<7120 6099 5357 5128 5065 5053>,
			<7199 6187 5377 5127 5061 5049>,
			<7281 6288 5404 5129 5064 5050>,
			<7365 6402 5436 5132 5067 5052>,
			<7449 6525 5476 5137 5068 5053>,
			<7531 6662 5524 5143 5067 5054>,
			<7625 6808 5570 5149 5065 5050>,
			<7727 6964 5625 5156 5063 5048>,
			<7821 7114 5668 5172 5072 5055>,
			<7734 7086 5682 5173 5078 5062>,
			<7823 7191 5748 5182 5087 5075>,
			<7918 7315 5823 5203 5101 5090>,
			<8016 7415 5907 5222 5103 5084>,
			<8118 7516 5969 5214 5086 5064>,
			<8232 7590 6048 5219 5085 5064>,
			<8378 7714 6209 5252 5096 5074>,
			<8945 7850 6420 5302 5125 5100>,
			<8945 7850 6420 5302 5125 5100>,
			<8945 7850 6420 5302 5125 5100>;
	};
};
